# STM32G07x register map
File version: 1.3
CPU: CM0+ r0p0, little endian, no MPU, no FPU, 3 interrupt priority bits
Registers are 32-bit, read-write, reset 0x0 unless marked. A register's access mark holds for its fields unless they carry their own. Offsets are from the block's base; [hi:lo] are bit positions; {n}, {i} and the like mark numbered series.

## SYSCFG_VREFBUF — System configuration controller
Base 0x40010000
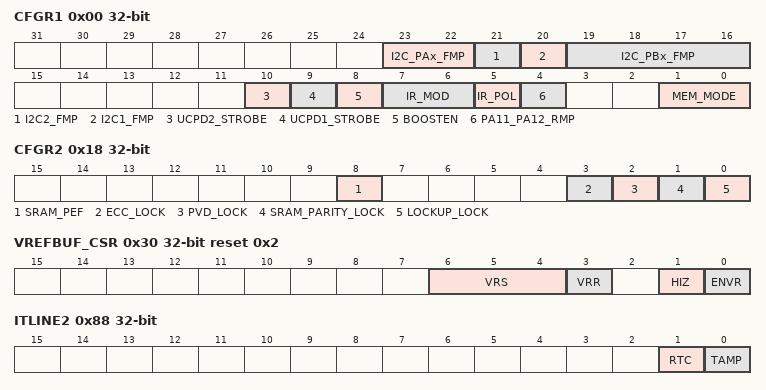
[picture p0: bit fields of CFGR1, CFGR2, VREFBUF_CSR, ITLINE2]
0x00 CFGR1 — SYSCFG configuration register 1
  [23:22] I2C_PAx_FMP — Fast Mode Plus (FM+) driving capability activation bits
  [21] I2C2_FMP — FM+ driving capability activation for I2C2
  [20] I2C1_FMP — FM+ driving capability activation for I2C1
  [19:16] I2C_PBx_FMP — Fast Mode Plus (FM+) driving capability activation bits
  [10] UCPD2_STROBE — Strobe signal bit for UCPD2
  [9] UCPD1_STROBE — Strobe signal bit for UCPD1
  [8] BOOSTEN — I/O analog switch voltage booster enable
  [7:6] IR_MOD — IR Modulation Envelope signal selection.
  [5] IR_POL — IR output polarity selection
  [4] PA11_PA12_RMP — PA11 and PA12 remapping bit.
  [1:0] MEM_MODE — Memory mapping selection bits
0x18 CFGR2 — SYSCFG configuration register 1
  [8] SRAM_PEF — SRAM parity error flag
  [3] ECC_LOCK — ECC error lock bit
  [2] PVD_LOCK — PVD lock enable bit
  [1] SRAM_PARITY_LOCK — SRAM parity lock bit
  [0] LOCKUP_LOCK — Cortex-M0+ LOCKUP bit enable bit
0x30 VREFBUF_CSR access per field reset 0x2 — VREFBUF control and status register
  [6:4] VRS rw — Voltage reference scale These bits select the value generated by the voltage reference buffer. Other: Reserved
  [3] VRR ro — Voltage reference buffer ready
  [1] HIZ rw — High impedance mode This bit controls the analog switch to connect or not the VREF+ pin. Refer to Table196: VREF buffer modes for the mode descriptions depending on ENVR bit configuration.
  [0] ENVR rw — Voltage reference buffer mode enable This bit is used to enable the voltage reference buffer mode.
0x34 VREFBUF_CCR — VREFBUF calibration control register
  [5:0] TRIM — Trimming code These bits are automatically initialized after reset with the trimming value stored in the Flash memory during the production test. Writing into these bits allows to tune the internal reference buffer voltage.
0x80 ITLINE0 ro — interrupt line 0 status register
  [0] WWDG — Window watchdog interrupt pending flag
0x84 ITLINE1 ro — interrupt line 1 status register
  [0] PVDOUT — PVD supply monitoring interrupt request pending (EXTI line 16).
0x88 ITLINE2 ro — interrupt line 2 status register
  [1] RTC, [0] TAMP
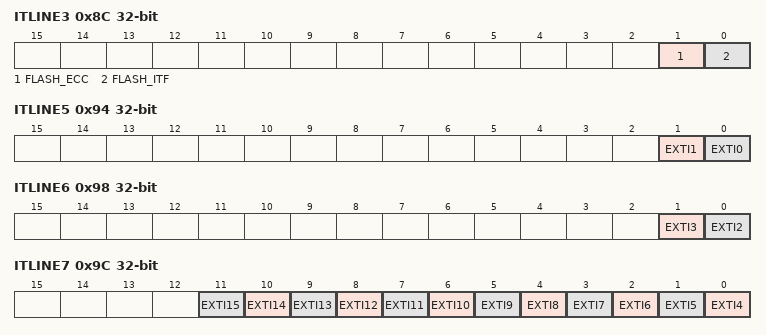
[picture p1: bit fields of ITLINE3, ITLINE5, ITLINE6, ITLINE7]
0x8C ITLINE3 ro — interrupt line 3 status register
  [1] FLASH_ECC, [0] FLASH_ITF
0x90 ITLINE4 ro — interrupt line 4 status register
  [0] RCC
0x94 ITLINE5 ro — interrupt line 5 status register
  [1] EXTI1, [0] EXTI0
0x98 ITLINE6 ro — interrupt line 6 status register
  [1] EXTI3, [0] EXTI2
0x9C ITLINE7 ro — interrupt line 7 status register
  [n-4] EXTI{n} (n=4..15)
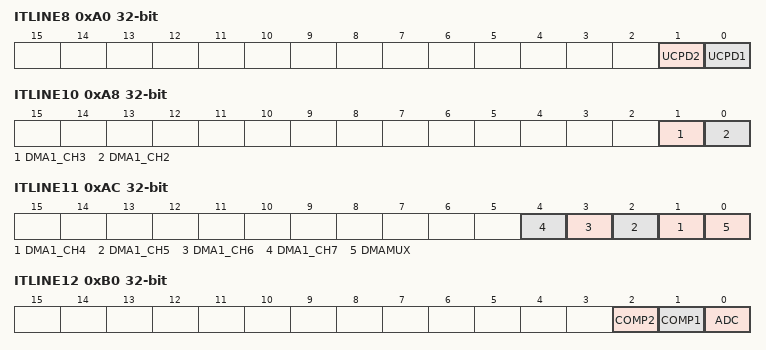
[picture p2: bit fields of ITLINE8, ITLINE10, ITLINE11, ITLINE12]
0xA0 ITLINE8 ro — interrupt line 8 status register
  [1] UCPD2, [0] UCPD1
0xA4 ITLINE9 ro — interrupt line 9 status register
  [0] DMA1_CH1
0xA8 ITLINE10 ro — interrupt line 10 status register
  [1] DMA1_CH3
  [0] DMA1_CH2 — DMA1_CH1
0xAC ITLINE11 ro — interrupt line 11 status register
  [n-3] DMA1_CH{n} (n=4..7), [0] DMAMUX
0xB0 ITLINE12 ro — interrupt line 12 status register
  [2] COMP2, [1] COMP1, [0] ADC
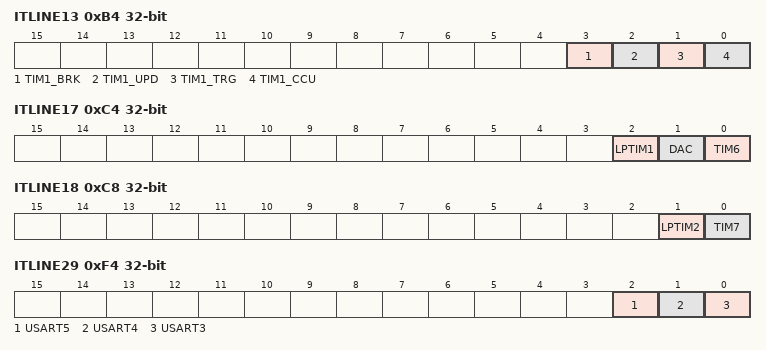
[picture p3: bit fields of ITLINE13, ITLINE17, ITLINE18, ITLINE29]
0xB4 ITLINE13 ro — interrupt line 13 status register
  [3] TIM1_BRK, [2] TIM1_UPD, [1] TIM1_TRG, [0] TIM1_CCU
0xB8 ITLINE14 ro — interrupt line 14 status register
  [0] TIM1_CC
0xBC ITLINE15 ro — interrupt line 15 status register
  [0] TIM2
0xC0 ITLINE16 ro — interrupt line 16 status register
  [0] TIM3
0xC4 ITLINE17 ro — interrupt line 17 status register
  [2] LPTIM1, [1] DAC, [0] TIM6
0xC8 ITLINE18 ro — interrupt line 18 status register
  [1] LPTIM2, [0] TIM7
{0x80+4i} ITLINE{i} ro (i=19..22) — interrupt line {i} status register
  [0] TIM{i-5}
0xDC ITLINE23 ro — interrupt line 23 status register
  [0] I2C1
0xE0 ITLINE24 ro — interrupt line 24 status register
  [0] I2C2
0xE4 ITLINE25 ro — interrupt line 25 status register
  [0] SPI1
0xE8 ITLINE26 ro — interrupt line 26 status register
  [0] SPI2
0xEC ITLINE27 ro — interrupt line 27 status register
  [0] USART1
0xF0 ITLINE28 ro — interrupt line 28 status register
  [0] USART2
0xF4 ITLINE29 ro — interrupt line 29 status register
  [2] USART5, [1] USART4, [0] USART3
0xF8 ITLINE30 ro — interrupt line 30 status register
  [0] USART2 — CEC
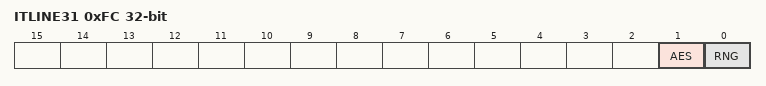
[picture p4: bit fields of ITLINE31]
0xFC ITLINE31 ro — interrupt line 31 status register
  [1] AES, [0] RNG
